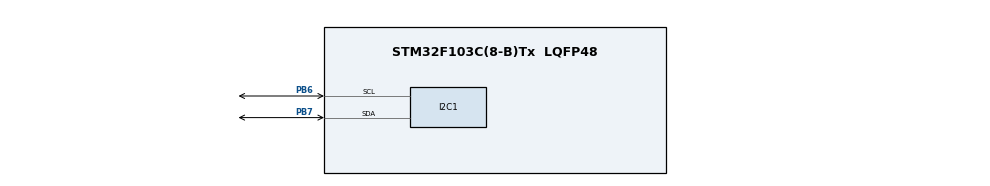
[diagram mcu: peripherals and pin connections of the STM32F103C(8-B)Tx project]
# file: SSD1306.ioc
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Mcu.Family=STM32F1
Mcu.Name=STM32F103C(8-B)Tx
Mcu.Package=LQFP48
NVIC.PriorityGroup=NVIC_PRIORITYGROUP_4
PA13.Mode=Serial_Wire
PA13.Signal=SYS_JTMS-SWDIO
PA14.Mode=Serial_Wire
PA14.Signal=SYS_JTCK-SWCLK
PB6.Mode=I2C
PB6.Signal=I2C1_SCL
PB7.Mode=I2C
PB7.Signal=I2C1_SDA
PD0-OSC_IN.Mode=HSE-External-Oscillator
PD0-OSC_IN.Signal=RCC_OSC_IN
PD1-OSC_OUT.Mode=HSE-External-Oscillator
PD1-OSC_OUT.Signal=RCC_OSC_OUT
ProjectManager.HeapSize=0x200
ProjectManager.StackSize=0x400
ProjectManager.TargetToolchain=STM32CubeIDE
RCC.AHBFreq_Value=72000000
RCC.APB1CLKDivider=RCC_HCLK_DIV2
RCC.APB1Freq_Value=36000000
RCC.APB1TimFreq_Value=72000000
RCC.APB2Freq_Value=72000000
RCC.APB2TimFreq_Value=72000000
RCC.HCLKFreq_Value=72000000
RCC.PLLMUL=RCC_PLL_MUL9
RCC.PLLSourceVirtual=RCC_PLLSOURCE_HSE
RCC.SYSCLKFreq_VALUE=72000000
RCC.SYSCLKSource=RCC_SYSCLKSOURCE_PLLCLK
RCC.USBFreq_Value=72000000
board=custom

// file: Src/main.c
/* USER CODE BEGIN Header */
/**
  ******************************************************************************
  * @file           : main.c
  * @brief          : Main program body
  ******************************************************************************
  * @attention
  *
  * <h2><center>&copy; Copyright (c) 2020 STMicroelectronics.
  * All rights reserved.</center></h2>
  *
  * This software component is licensed by ST under BSD 3-Clause license,
  * the "License"; You may not use this file except in compliance with the
  * License. You may obtain a copy of the License at:
  *                        opensource.org/licenses/BSD-3-Clause
  *
  ******************************************************************************
  */
/* USER CODE END Header */

#include "main.h"

/* USER CODE BEGIN Includes */
#include "ssd1306.h"
#include "fontsA.h"
/* USER CODE END Includes */

void SystemClock_Config(void);
static void MX_GPIO_Init(void);
static void MX_I2C1_Init(void);

int main(void)
{

  /* MCU Configuration--------------------------------------------------------*/

  /* Reset of all peripherals, Initializes the Flash interface and the Systick. */

  LL_APB2_GRP1_EnableClock(LL_APB2_GRP1_PERIPH_AFIO);
  LL_APB1_GRP1_EnableClock(LL_APB1_GRP1_PERIPH_PWR);

  NVIC_SetPriorityGrouping(NVIC_PRIORITYGROUP_4);

  /* System interrupt init*/

  /** NOJTAG: JTAG-DP Disabled and SW-DP Enabled
  */
  LL_GPIO_AF_Remap_SWJ_NOJTAG();

  /* Configure the system clock */
  SystemClock_Config();

  /* Initialize all configured peripherals */
  MX_GPIO_Init();
  MX_I2C1_Init();
  /* USER CODE BEGIN 2 */
  ssd1306_Init();

  /* USER CODE END 2 */

  /* Infinite loop */
  /* USER CODE BEGIN WHILE */
  while (1)
  {
	  ssd1306_Fill(Black);
	  ssd1306_DrawText("SSD1306 Library", FONT1, 0,0, White);
	  ssd1306_DrawText("LL Drivers STM32F1", FONT1, 0,14, White);
	  ssd1306_UpdateScreen();
	  LL_mDelay(2000);
	  ssd1306_Fill(Black);
	  ssd1306_DrawText("Custom Fonts", FONT2, 0,0, White);
	  ssd1306_UpdateScreen();
	  LL_mDelay(2000);
  }
  /* USER CODE END 3 */
}

void SystemClock_Config(void)
{
  LL_FLASH_SetLatency(LL_FLASH_LATENCY_2);

   if(LL_FLASH_GetLatency() != LL_FLASH_LATENCY_2)
  {
    Error_Handler();
  }
  LL_RCC_HSE_Enable();

   /* Wait till HSE is ready */
  while(LL_RCC_HSE_IsReady() != 1)
  {

  }
  LL_RCC_PLL_ConfigDomain_SYS(LL_RCC_PLLSOURCE_HSE_DIV_1, LL_RCC_PLL_MUL_9);
  LL_RCC_PLL_Enable();

   /* Wait till PLL is ready */
  while(LL_RCC_PLL_IsReady() != 1)
  {

  }
  LL_RCC_SetAHBPrescaler(LL_RCC_SYSCLK_DIV_1);
  LL_RCC_SetAPB1Prescaler(LL_RCC_APB1_DIV_2);
  LL_RCC_SetAPB2Prescaler(LL_RCC_APB2_DIV_1);
  LL_RCC_SetSysClkSource(LL_RCC_SYS_CLKSOURCE_PLL);

   /* Wait till System clock is ready */
  while(LL_RCC_GetSysClkSource() != LL_RCC_SYS_CLKSOURCE_STATUS_PLL)
  {

  }
  LL_Init1msTick(72000000);
  LL_SetSystemCoreClock(72000000);
}

static void MX_I2C1_Init(void)
{

  LL_I2C_InitTypeDef I2C_InitStruct = {0};

  LL_GPIO_InitTypeDef GPIO_InitStruct = {0};

  LL_APB2_GRP1_EnableClock(LL_APB2_GRP1_PERIPH_GPIOB);
  /**I2C1 GPIO Configuration
  PB6   ------> I2C1_SCL
  PB7   ------> I2C1_SDA
  */
  GPIO_InitStruct.Pin = LL_GPIO_PIN_6|LL_GPIO_PIN_7;
  GPIO_InitStruct.Mode = LL_GPIO_MODE_ALTERNATE;
  GPIO_InitStruct.Speed = LL_GPIO_SPEED_FREQ_HIGH;
  GPIO_InitStruct.OutputType = LL_GPIO_OUTPUT_OPENDRAIN;
  LL_GPIO_Init(GPIOB, &GPIO_InitStruct);

  /* Peripheral clock enable */
  LL_APB1_GRP1_EnableClock(LL_APB1_GRP1_PERIPH_I2C1);

  /** I2C Initialization
  */
  LL_I2C_DisableOwnAddress2(I2C1);
  LL_I2C_DisableGeneralCall(I2C1);
  LL_I2C_EnableClockStretching(I2C1);
  I2C_InitStruct.PeripheralMode = LL_I2C_MODE_I2C;
  I2C_InitStruct.ClockSpeed = 100000;
  I2C_InitStruct.DutyCycle = LL_I2C_DUTYCYCLE_2;
  I2C_InitStruct.OwnAddress1 = 0;
  I2C_InitStruct.TypeAcknowledge = LL_I2C_ACK;
  I2C_InitStruct.OwnAddrSize = LL_I2C_OWNADDRESS1_7BIT;
  LL_I2C_Init(I2C1, &I2C_InitStruct);
  LL_I2C_SetOwnAddress2(I2C1, 0);
  /* USER CODE BEGIN I2C1_Init 2 */
  LL_I2C_Enable(I2C2);
  /* USER CODE END I2C1_Init 2 */

}

static void MX_GPIO_Init(void)
{

  /* GPIO Ports Clock Enable */
  LL_APB2_GRP1_EnableClock(LL_APB2_GRP1_PERIPH_GPIOD);
  LL_APB2_GRP1_EnableClock(LL_APB2_GRP1_PERIPH_GPIOA);
  LL_APB2_GRP1_EnableClock(LL_APB2_GRP1_PERIPH_GPIOB);

}

void Error_Handler(void)
{

}

/************************ (C) COPYRIGHT STMicroelectronics *****END OF FILE****/
